# PIC32CX5112MTSH128S1 device description
Architecture: CORTEX-M4; Family: PIC32CXMT; Series: PIC32CXMTSH
Registers are 32-bit, read-write, no defined reset value unless marked. A register's access mark holds for its fields unless they carry their own. Offsets are from the block's base; [hi:lo] are bit positions; lines under a group give offsets from that group; {n}, {i} and the like mark numbered series; 'fields as' and 'values as' point back to an identical list; <NAME> marks a mode.

## PIO — Parallel Input/Output Controller
Instances: PIO0 0x40048000, PIO1 0x4800C000
{0x0+0x40*i} PIO_GROUP[{i}] (i=0..2) group
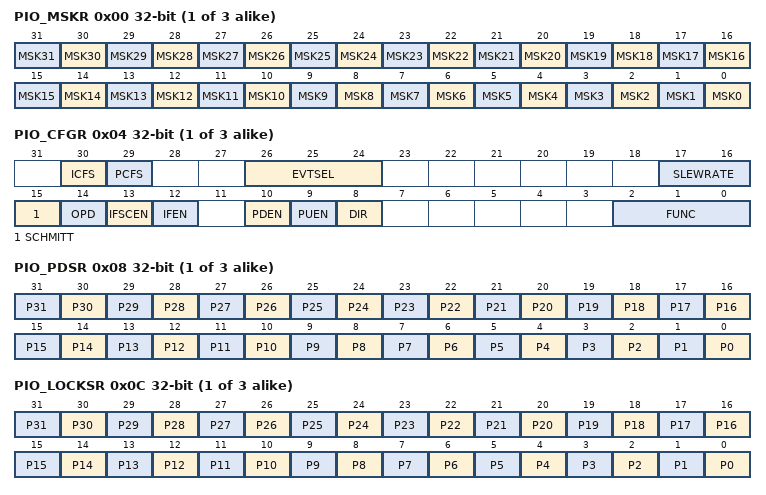
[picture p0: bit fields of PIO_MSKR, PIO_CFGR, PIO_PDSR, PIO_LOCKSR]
  0x00 PIO_MSKR — PIO Mask Register
    [all] fields
      0=DISABLED (Writing the PIO_CFGRx, PIO_ODSRx or PIO_IOFRx does not affect the corresponding I/O line configuration.); 1=ENABLED (Writing the PIO_CFGRx, PIO_ODSRx or PIO_IOFRx updates the corresponding I/O line configuration.)
    [n] MSK{n} (n=0..31) — PIO Line {n} Mask
  0x04 PIO_CFGR — PIO Configuration Register
    [30] ICFS — Interrupt Configuration Freeze Status (read-only)
      0=NOT_FROZEN (The fields are not frozen and can be written for this I/O line.); 1=FROZEN (The fields are frozen and cannot be written for this I/O line. Only a hardware reset can release these fields.)
    [29] PCFS — Physical Configuration Freeze Status (read-only)
      values as ICFS
    [26:24] EVTSEL — Event Selection
      0=FALLING (Event detection on input falling edge); 1=RISING (Event detection on input rising edge); 2=BOTH (Event detection on input both edge); 3=LOW (Event detection on low level input); 4=HIGH (Event detection on high level input)
    [17:16] SLEWRATE
      0=FAST (Fast slew rate); 1=MEDIUMFAST (Medium-fast slew rate); 2=MEDIUM (Medium slew rate); 3=SLOW (Slow slew rate)
    [15] SCHMITT — Schmitt Trigger
      0=ENABLED (Schmitt trigger is enabled for the selected I/O lines.); 1=DISABLED (Schmitt trigger is disabled for the selected I/O lines.)
    [14] OPD — Open-Drain
      0=DISABLED (The open-drain is disabled for the selected I/O lines. I/O lines are driven at high- and low-level.); 1=ENABLED (The open-drain is enabled for the selected I/O lines. I/O lines are driven at low-level only.)
    [13] IFSCEN — Input Filter Slow Clock Enable
      0=DISABLED (The glitch filter is able to filter glitches with a duration < tmck/2 for the selected I/O lines.); 1=ENABLED (The debouncing filter is able to filter pulses with a duration < tdiv_slck/2 for the selected I/O lines.)
    [12] IFEN — Input Filter Enable
      0=DISABLED (The input filter is disabled for the selected I/O lines.); 1=ENABLED (The input filter is enabled for the selected I/O lines.)
    [10] PDEN — Pull-Down Enable
      0=DISABLED (Pull-Down is disabled for the selected I/O lines.); 1=ENABLED (Pull-Down is enabled for the selected I/O lines only if PUEN is 0.)
    [9] PUEN — Pull-Up Enable
      0=DISABLED (Pull-Up is disabled for the selected I/O lines.); 1=ENABLED (Pull-Up is enabled for the selected I/O lines.)
    [8] DIR — Direction
      0=INPUT (The selected I/O lines are pure inputs.); 1=OUTPUT (The selected I/O lines are enabled in output.)
    [2:0] FUNC — I/O Line Function
      0=GPIO (Select the PIO mode for the selected I/O lines.); 1=PERIPH_A (Select the peripheral A for the selected I/O lines.); 2=PERIPH_B (Select the peripheral B for the selected I/O lines.); 3=PERIPH_C (Select the peripheral C for the selected I/O lines.); 4=PERIPH_D (Select the peripheral D for the selected I/O lines.)
  0x08 PIO_PDSR ro — PIO Pin Data Status Register
    [n] P{n} (n=0..31) — Input Data Status
  0x0C PIO_LOCKSR ro — PIO Lock Status Register
    [n] P{n} (n=0..31) — Lock Status
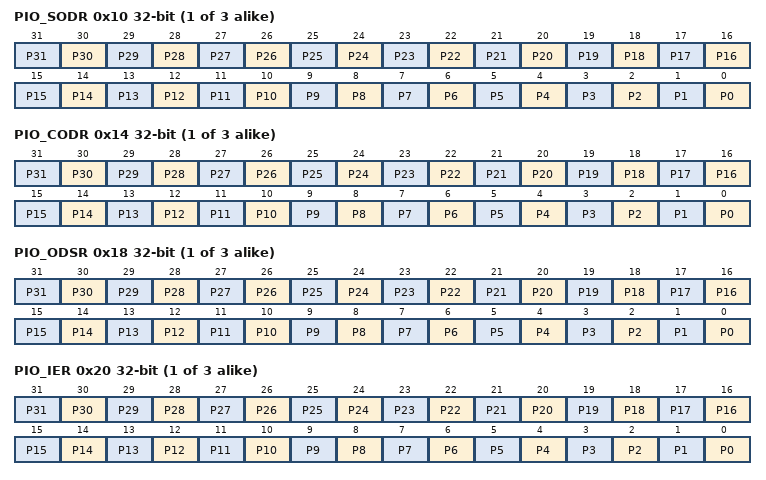
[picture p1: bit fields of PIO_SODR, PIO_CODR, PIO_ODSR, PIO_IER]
  0x10 PIO_SODR wo — PIO Set Output Data Register
    [n] P{n} (n=0..31) — Set Output Data
  0x14 PIO_CODR wo — PIO Clear Output Data Register
    [n] P{n} (n=0..31) — Clear Output Data
  0x18 PIO_ODSR — PIO Output Data Status Register
    [n] P{n} (n=0..31) — Output Data Status
  0x20 PIO_IER wo — PIO Interrupt Enable Register
    [n] P{n} (n=0..31) — Input Change Interrupt Enable
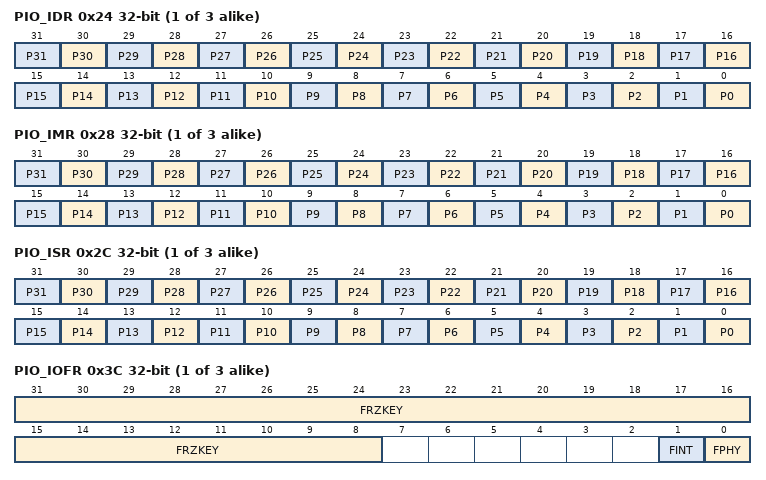
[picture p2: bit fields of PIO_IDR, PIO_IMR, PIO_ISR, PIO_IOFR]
  0x24 PIO_IDR wo — PIO Interrupt Disable Register
    [n] P{n} (n=0..31) — Input Change Interrupt Disable
  0x28 PIO_IMR ro — PIO Interrupt Mask Register
    [n] P{n} (n=0..31) — Input Change Interrupt Mask
  0x2C PIO_ISR ro — PIO Interrupt Status Register
    [n] P{n} (n=0..31) — Input Change Interrupt Status
  0x3C PIO_IOFR wo — PIO I/O Freeze Configuration Register
    [31:8] FRZKEY — Freeze Key
      0x494F46=PASSWD (Writing any other value in this field aborts the write operation of the WPEN bit.)
    [1] FINT — Freeze Interrupt Configuration
    [0] FPHY — Freeze Physical Configuration
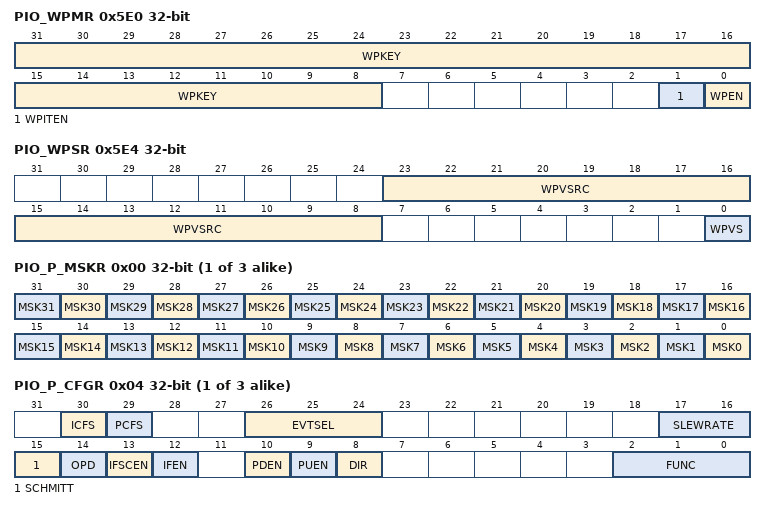
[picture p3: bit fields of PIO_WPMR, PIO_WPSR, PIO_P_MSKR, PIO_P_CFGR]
0x5E0 PIO_WPMR — PIO Write Protection Mode Register
  [31:8] WPKEY — Write Protection Key
    0x50494F=PASSWD (Writing any other value in this field aborts the write operation of the WPEN bit. Always reads as 0.)
  [1] WPITEN — Write Protection Interrupt Enable
  [0] WPEN — Write Protection Enable
0x5E4 PIO_WPSR ro — PIO Write Protection Status Register
  [23:8] WPVSRC — Write Protection Violation Source
  [0] WPVS — Write Protection Violation Status
{0x1000+0x40*i} PIO_P[{i}] (i=0..2) group
  0x00 PIO_P_MSKR — PIO Privilege Mask Register (p_iogroup = 0)
    [all] fields
      0=DISABLED (Writing the PIO_P_CFGRx, PIO_P_ODSRx or PIO_P_IOFRx does not affect the corresponding I/O line configuration.); 1=ENABLED (Writing the PIO_P_CFGRx, PIO_P_ODSRx or PIO_P_IOFRX updates the corresponding I/O line configuration.)
    [n] MSK{n} (n=0..31) — PIO Line {n} Mask
  0x04 PIO_P_CFGR — PIO Privilege Configuration Register (p_iogroup = 0)
    [30] ICFS — Interrupt Configuration Freeze Status (read-only)
      values as PIO_GROUP[0].PIO_CFGR.ICFS
    [29] PCFS — Physical Configuration Freeze Status (read-only)
      values as PIO_GROUP[0].PIO_CFGR.ICFS
    [26:24] EVTSEL — Event Selection
      values as PIO_GROUP[0].PIO_CFGR.EVTSEL
    [17:16] SLEWRATE
      0=FAST (Slow slew rate); 1=MEDIUMFAST (Medium-fast slew rate); 2=MEDIUM (Medium slew rate); 3=SLOW (Slow slew rate)
    [15] SCHMITT — Schmitt Trigger
      values as PIO_GROUP[0].PIO_CFGR.SCHMITT
    [14] OPD — Open-Drain
      values as PIO_GROUP[0].PIO_CFGR.OPD
    [13] IFSCEN — Input Filter Slow Clock Enable
    [12] IFEN — Input Filter Enable
      values as PIO_GROUP[0].PIO_CFGR.IFEN
    [10] PDEN — Pull-Down Enable
      values as PIO_GROUP[0].PIO_CFGR.PDEN
    [9] PUEN — Pull-Up Enable
      values as PIO_GROUP[0].PIO_CFGR.PUEN
    [8] DIR — Direction
      values as PIO_GROUP[0].PIO_CFGR.DIR
    [2:0] FUNC — I/O Line Function
      values as PIO_GROUP[0].PIO_CFGR.FUNC
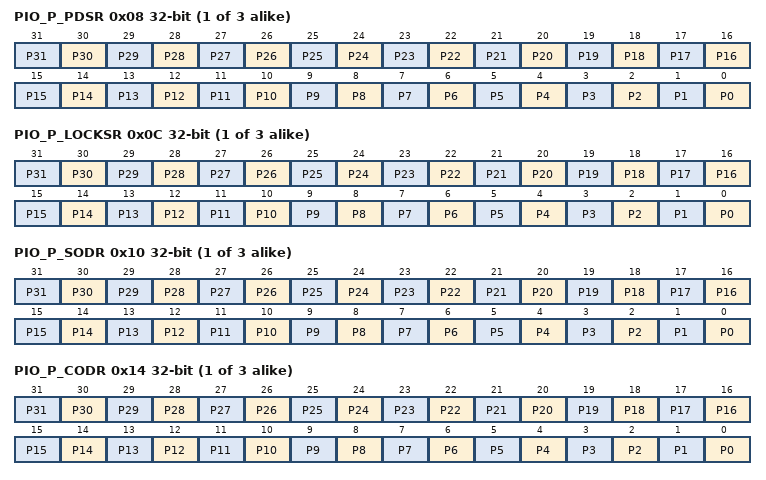
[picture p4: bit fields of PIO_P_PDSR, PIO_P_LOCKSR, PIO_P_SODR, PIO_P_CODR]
  0x08 PIO_P_PDSR ro — PIO Privilege Pin Data Status Register (p_iogroup = 0)
    [n] P{n} (n=0..31) — Input Data Status
  0x0C PIO_P_LOCKSR ro — PIO Privilege Lock Status Register (p_iogroup = 0)
    [n] P{n} (n=0..31) — Lock Status
  0x10 PIO_P_SODR wo — PIO Privilege Set Output Data Register (p_iogroup = 0)
    [n] P{n} (n=0..31) — Set Output Data
  0x14 PIO_P_CODR wo — PIO Privilege Clear Output Data Register (p_iogroup = 0)
    [n] P{n} (n=0..31) — Clear Output Data
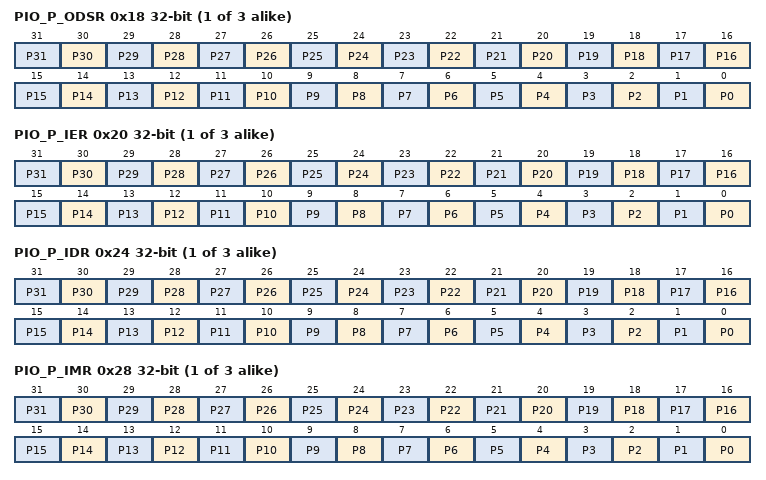
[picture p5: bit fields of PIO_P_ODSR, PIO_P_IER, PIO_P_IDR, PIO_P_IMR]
  0x18 PIO_P_ODSR — PIO Privilege Output Data Status Register (p_iogroup = 0)
    [n] P{n} (n=0..31) — Output Data Status
  0x20 PIO_P_IER wo — PIO Privilege Interrupt Enable Register (p_iogroup = 0)
    [n] P{n} (n=0..31) — Input Change Interrupt Enable
  0x24 PIO_P_IDR wo — PIO Privilege Interrupt Disable Register (p_iogroup = 0)
    [n] P{n} (n=0..31) — Input Change Interrupt Disable
  0x28 PIO_P_IMR ro — PIO Privilege Interrupt Mask Register (p_iogroup = 0)
    [n] P{n} (n=0..31) — Input Change Interrupt Mask
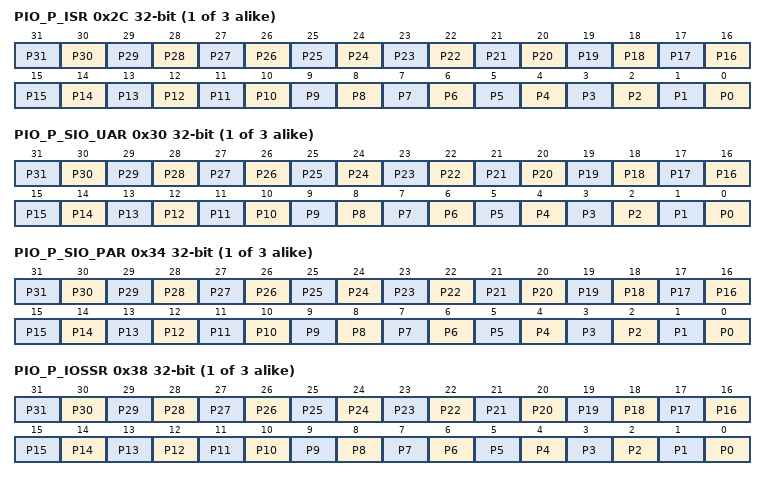
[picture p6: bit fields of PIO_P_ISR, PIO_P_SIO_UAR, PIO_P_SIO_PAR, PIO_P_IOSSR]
  0x2C PIO_P_ISR ro — PIO Privilege Interrupt Status Register (p_iogroup = 0)
    [n] P{n} (n=0..31) — Input Change Interrupt Status
  0x30 PIO_P_SIO_UAR wo — PIO Privilege Set I/O User Register (p_iogroup = 0)
    [n] P{n} (n=0..31) — Set I/O in User-Access mode
  0x34 PIO_P_SIO_PAR wo — PIO Privilege Set I/O Privilege Register (p_iogroup = 0)
    [n] P{n} (n=0..31) — Set I/O in Privileged-Access mode
  0x38 PIO_P_IOSSR ro — PIO Privilege I/O Security Status Register (p_iogroup = 0)
    [all] fields
      0=PRIVILEGED_ACCESS (The I/O line of the I/O group 0 is in Privileged-Access mode.); 1=USER_ACCESS (The I/O line of the I/O group 0 is in User-Access mode.)
    [n] P{n} (n=0..31) — I/O Security Status
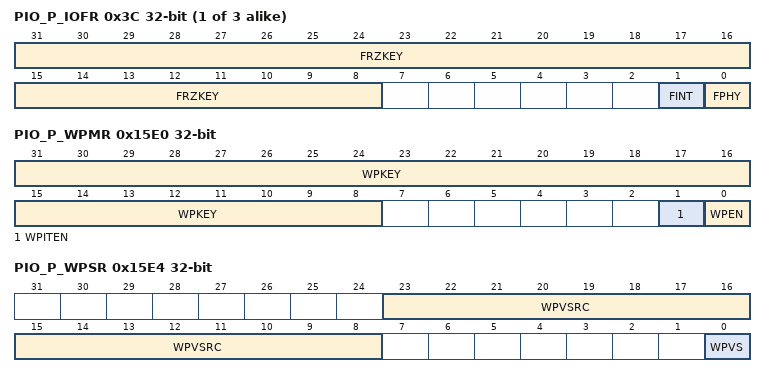
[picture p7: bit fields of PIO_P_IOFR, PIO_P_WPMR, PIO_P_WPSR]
  0x3C PIO_P_IOFR wo — PIO Privilege I/O Freeze Configuration Register (p_iogroup = 0)
    fields as PIO_GROUP[0].PIO_IOFR
0x1500 PIO_P_SCDR — PIO Privilege Slow Clock Divider Debouncing Register
  [13:0] DIV — Slow Clock Divider Selection for Debouncing
0x15E0 PIO_P_WPMR — PIO Privilege Write Protection Mode Register
  [31:8] WPKEY — Write Protection Key
    0x50494F=PASSWD (Writing any other value in this field aborts the write operation of WPEN. Always reads as 0.)
  [1] WPITEN — Write Protection Interrupt Enable
  [0] WPEN — Write Protection Enable
0x15E4 PIO_P_WPSR ro — PIO Privilege Write Protection Status Register
  fields as PIO_WPSR
